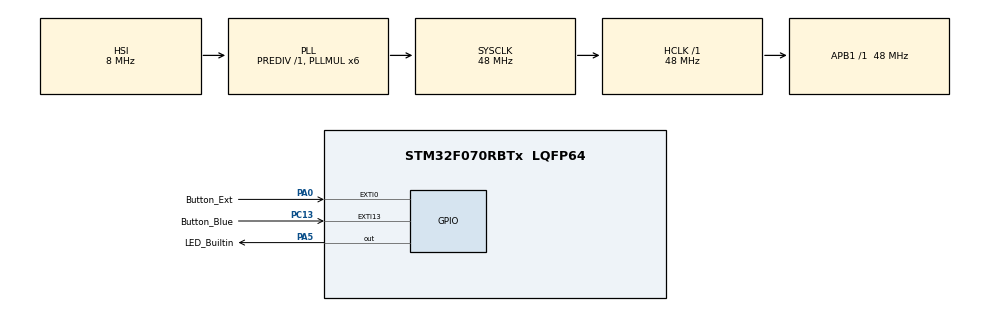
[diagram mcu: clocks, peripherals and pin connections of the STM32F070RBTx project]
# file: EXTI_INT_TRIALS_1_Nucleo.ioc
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Mcu.Family=STM32F0
Mcu.Name=STM32F070RBTx
Mcu.Package=LQFP64
NVIC.EXTI0_1_IRQn=true\:2\:0\:true\:false\:true\:true\:true\:true
NVIC.EXTI4_15_IRQn=true\:1\:0\:true\:false\:true\:true\:true\:true
NVIC.TIM6_IRQn=true\:3\:0\:true\:false\:true\:true\:true\:true
PA0.GPIO_Label=Button_Ext
PA0.GPIO_ModeDefaultEXTI=GPIO_MODE_IT_RISING
PA0.GPIO_PuPd=GPIO_PULLDOWN
PA0.Signal=GPXTI0
PA13.GPIO_Label=TMS
PA13.Mode=Serial_Wire
PA13.Signal=SYS_SWDIO
PA14.GPIO_Label=TCK
PA14.Mode=Serial_Wire
PA14.Signal=SYS_SWCLK
PA5.GPIO_Label=LED_Builtin
PA5.Signal=GPIO_Output
PC13.GPIO_Label=Button_Blue
PC13.GPIO_PuPd=GPIO_PULLDOWN
PC13.Signal=GPXTI13
PC14-OSC32_IN.Mode=LSE-External-Oscillator
PC14-OSC32_IN.Signal=RCC_OSC32_IN
PC15-OSC32_OUT.Mode=LSE-External-Oscillator
PC15-OSC32_OUT.Signal=RCC_OSC32_OUT
PF0-OSC_IN.GPIO_Label=RCC_OSC_IN
PF0-OSC_IN.Mode=HSE-External-Clock-Source
PF0-OSC_IN.Signal=RCC_OSC_IN
PF1-OSC_OUT.GPIO_Label=RCC_OSC_OUT
PF1-OSC_OUT.Signal=RCC_OSC_OUT
ProjectManager.HeapSize=0x200
ProjectManager.StackSize=0x400
ProjectManager.TargetToolchain=STM32CubeIDE
RCC.AHBFreq_Value=48000000
RCC.APB1Freq_Value=48000000
RCC.APB1TimFreq_Value=48000000
RCC.HCLKFreq_Value=48000000
RCC.PLLMUL=RCC_PLL_MUL6
RCC.SYSCLKFreq_VALUE=48000000
RCC.SYSCLKSource=RCC_SYSCLKSOURCE_PLLCLK
TIM6.Period=1-1
TIM6.Prescaler=48000-1
VP_TIM6_VS_ClockSourceINT.Mode=Enable_Timer
board=NUCLEO-F070RB

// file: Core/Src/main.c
/* USER CODE BEGIN Header */
/**
  ******************************************************************************
  * @file           : main.c
  * @brief          : Main program body
  ******************************************************************************
  * @attention
  *
  * Copyright (c) 2023 STMicroelectronics.
  * All rights reserved.
  *
  * This software is licensed under terms that can be found in the LICENSE file
  * in the root directory of this software component.
  * If no LICENSE file comes with this software, it is provided AS-IS.
  *
  ******************************************************************************
  */
/* USER CODE END Header */
#include "main.h"

/* USER CODE BEGIN PD */

uint8_t State = 0;
uint32_t SecondCounter = 0;

volatile uint32_t millis = 0;
volatile uint32_t delayStartTime = 0;
volatile uint32_t delayDuration = 0;

/* USER CODE END PD */

TIM_HandleTypeDef htim6;

void SystemClock_Config(void);
static void MX_GPIO_Init(void);
static void MX_TIM6_Init(void);

int main(void)
{

  /* MCU Configuration--------------------------------------------------------*/

  /* Reset of all peripherals, Initializes the Flash interface and the Systick. */
  HAL_Init();

  /* Configure the system clock */
  SystemClock_Config();

  /* Initialize all configured peripherals */
  MX_GPIO_Init();
  MX_TIM6_Init();
  /* USER CODE BEGIN 2 */

  HAL_TIM_Base_Start_IT(&htim6); // htim3 handleli timeri interrupt modunda baslattik.

  HAL_SYSTICK_Config(HAL_RCC_GetHCLKFreq() / 1000);  // Configure SysTick for 1ms

  /* USER CODE END 2 */

  /* Infinite loop */
  /* USER CODE BEGIN WHILE */
  while (1)
  {

      if ((millis - delayStartTime) >= delayDuration)
      {
          State = 0;
      }
    /* USER CODE END WHILE */

  }
}

void SystemClock_Config(void)
{
  RCC_OscInitTypeDef RCC_OscInitStruct = {0};
  RCC_ClkInitTypeDef RCC_ClkInitStruct = {0};

  /** Initializes the RCC Oscillators according to the specified parameters
  * in the RCC_OscInitTypeDef structure.
  */
  RCC_OscInitStruct.OscillatorType = RCC_OSCILLATORTYPE_HSI;
  RCC_OscInitStruct.HSIState = RCC_HSI_ON;
  RCC_OscInitStruct.HSICalibrationValue = RCC_HSICALIBRATION_DEFAULT;
  RCC_OscInitStruct.PLL.PLLState = RCC_PLL_ON;
  RCC_OscInitStruct.PLL.PLLSource = RCC_PLLSOURCE_HSI;
  RCC_OscInitStruct.PLL.PLLMUL = RCC_PLL_MUL6;
  RCC_OscInitStruct.PLL.PREDIV = RCC_PREDIV_DIV1;
  if (HAL_RCC_OscConfig(&RCC_OscInitStruct) != HAL_OK)
  {
    Error_Handler();
  }

  /** Initializes the CPU, AHB and APB buses clocks
  */
  RCC_ClkInitStruct.ClockType = RCC_CLOCKTYPE_HCLK|RCC_CLOCKTYPE_SYSCLK
                              |RCC_CLOCKTYPE_PCLK1;
  RCC_ClkInitStruct.SYSCLKSource = RCC_SYSCLKSOURCE_PLLCLK;
  RCC_ClkInitStruct.AHBCLKDivider = RCC_SYSCLK_DIV1;
  RCC_ClkInitStruct.APB1CLKDivider = RCC_HCLK_DIV1;

  if (HAL_RCC_ClockConfig(&RCC_ClkInitStruct, FLASH_LATENCY_1) != HAL_OK)
  {
    Error_Handler();
  }
}

static void MX_TIM6_Init(void)
{

  htim6.Instance = TIM6;
  htim6.Init.Prescaler = 48000-1;
  htim6.Init.CounterMode = TIM_COUNTERMODE_UP;
  htim6.Init.Period = 1-1;
  htim6.Init.AutoReloadPreload = TIM_AUTORELOAD_PRELOAD_DISABLE;
  if (HAL_TIM_Base_Init(&htim6) != HAL_OK)
  {
    Error_Handler();
  }

}

static void MX_GPIO_Init(void)
{
  GPIO_InitTypeDef GPIO_InitStruct = {0};

  /* GPIO Ports Clock Enable */
  __HAL_RCC_GPIOC_CLK_ENABLE();
  __HAL_RCC_GPIOF_CLK_ENABLE();
  __HAL_RCC_GPIOA_CLK_ENABLE();

  /*Configure GPIO pin Output Level */
  HAL_GPIO_WritePin(LED_Builtin_GPIO_Port, LED_Builtin_Pin, GPIO_PIN_RESET);

  /*Configure GPIO pin : Button_Blue_Pin */
  GPIO_InitStruct.Pin = Button_Blue_Pin;
  GPIO_InitStruct.Mode = GPIO_MODE_IT_RISING;
  GPIO_InitStruct.Pull = GPIO_PULLDOWN;
  HAL_GPIO_Init(Button_Blue_GPIO_Port, &GPIO_InitStruct);

  /*Configure GPIO pin : Button_Ext_Pin */
  GPIO_InitStruct.Pin = Button_Ext_Pin;
  GPIO_InitStruct.Mode = GPIO_MODE_IT_RISING;
  GPIO_InitStruct.Pull = GPIO_PULLDOWN;
  HAL_GPIO_Init(Button_Ext_GPIO_Port, &GPIO_InitStruct);

  /*Configure GPIO pin : LED_Builtin_Pin */
  GPIO_InitStruct.Pin = LED_Builtin_Pin;
  GPIO_InitStruct.Mode = GPIO_MODE_OUTPUT_PP;
  GPIO_InitStruct.Pull = GPIO_NOPULL;
  GPIO_InitStruct.Speed = GPIO_SPEED_FREQ_LOW;
  HAL_GPIO_Init(LED_Builtin_GPIO_Port, &GPIO_InitStruct);

  /* EXTI interrupt init*/
  HAL_NVIC_SetPriority(EXTI0_1_IRQn, 2, 0);
  HAL_NVIC_EnableIRQ(EXTI0_1_IRQn);

  HAL_NVIC_SetPriority(EXTI4_15_IRQn, 1, 0);
  HAL_NVIC_EnableIRQ(EXTI4_15_IRQn);

}

/* USER CODE BEGIN 4 */

/*// This should be done inside of ioc file or startup.c file
void SysTick_Handler(void)
{
    millis++;
}
*/

void HAL_GPIO_EXTI_Callback(uint16_t GPIO_Pin)
{

	if (GPIO_Pin == Button_Blue_Pin)
	{
		State = 1;
		delayStartTime = millis;
		delayDuration = 3000;

	}

	else if (GPIO_Pin == Button_Ext_Pin)
	{
		State = 2;
		delayStartTime = millis;
		delayDuration = 3000;
	}
}

/*
void HAL_TIM_PeriodElapsedCallback(TIM_HandleTypeDef *htim)
{

	if (htim == &htim6)
	{
		SecondCounter++;
	}
}
*/

/* USER CODE END 4 */

void Error_Handler(void)
{
  __disable_irq();
  while (1)
  {
  }
}
